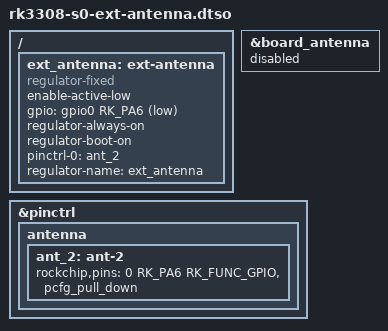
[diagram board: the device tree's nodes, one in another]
//Select Rock S0's external WiFi antenna input
//(instead of default internal WiFi antenna)

/dts-v1/;
/plugin/;
#include <dt-bindings/gpio/gpio.h>
#include <dt-bindings/pinctrl/rockchip.h>

/ {
	fragment@0 {
		target-path = "/";

		__overlay__ {
			ext_antenna: ext-antenna {
				status = "okay";
				compatible = "regulator-fixed";
				enable-active-low;
				gpio = <&gpio0 RK_PA6 GPIO_ACTIVE_LOW>;
				regulator-always-on;
				regulator-boot-on;
				pinctrl-0 = <&ant_2>;
				pinctrl-names = "default";
				regulator-name = "ext_antenna";
			};
		};
	};

	fragment@1 {
		target = <&board_antenna>;

		__overlay__ {
			status = "disabled";
		};
	};

	fragment@2 {
		target = <&pinctrl>;

		__overlay__ {
			antenna {
				ant_2: ant-2 {
					rockchip,pins = <0 RK_PA6 RK_FUNC_GPIO &pcfg_pull_down>;
				};
			};
		};
	};
};

